# DWC_ahsata register map
Vendor: Texas Instruments
Peripheral module from a debugger description file (folder am572x).
Registers are 32-bit, read-only, reset 0x0 unless marked. A register's access mark holds for its fields unless they carry their own. Offsets are as the file gives them; lines under a group give offsets from that group; [hi:lo] are bit positions; {n}, {i} and the like mark numbered series; 'fields as' and 'values as' point back to an identical list; <NAME> marks a mode.

## DWC_ahsata
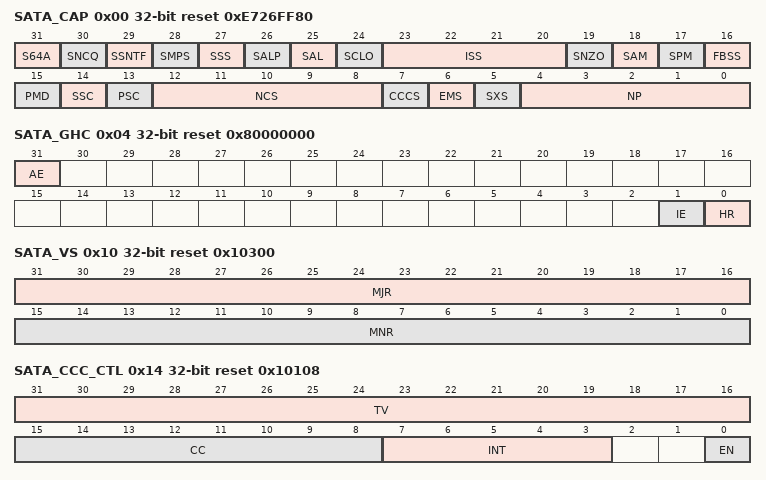
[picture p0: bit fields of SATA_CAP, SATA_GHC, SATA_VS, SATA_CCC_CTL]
0x00 SATA_CAP access not given reset 0xE726FF80 — Capabilities register: Basic capabilities of the SATA AHCI core. Some fields can be written once after reset, read-only.
  [31] S64A ro — Supports 64-bit addressing
    1=64-bit addressing supported; 0=32-bit addressing supported
  [30] SNCQ ro — Supports NCQ (Native Command Queuing) Controller supports SATA NCQ by handling DMA setup FIS natively.
    1=YES (Supported); 0=NO (Not supported)
  [29] SSNTF ro — Supports SNotification register Controller supports SATA_PxSNTF (SNotification) register and its associated functionality.
    1=YES (Supported); 0=NO (Not supported)
  [28] SMPS — Supports mechanical presence switch Support of a mechanical presence switch for hot plug operation, depending on integration Writable once after power up, read-only afterward (access RW WSpecial)
    0=NO (Not supported); 1=YES (Supported)
  [27] SSS — Supports staggered spin-up Controller can support this feature through SATA_PxCMD.SUD Writable once after power up, read-only afterward (access RW WSpecial)
    0=NO (Not supported); 1=YES (Supported)
  [26] SALP ro — Supports aggressive link power management
    1=YES (Supported); 0=NO (Not supported)
  [25] SAL ro — Supports Activity LED
    1=YES (Supported); 0=NO (Not supported)
  [24] SCLO ro — Supports command list override Supports the SATA_PxCMD.CLO bit functionality for enumeration of PM devices
    1=YES (Supported); 0=NO (Not supported)
  [23:20] ISS ro — Interface speed support Maximum speed the HBA can support
    3=ISS_3_r (Gen 3 = 6 Gbps); 2=ISS_2_r (Gen 2 = 3 Gbps); 1=1G5 (Gen 1 = 1.5 Gbps)
  [19] SNZO ro — Supports Non-zero DMA offsets
    1=YES (Supported); 0=NO (Not supported)
  [18] SAM ro — Supports AHCI mode only SATA controller supports AHCI mode only and does not support legacy, task file-based register interface.
    1=YES (Supported); 0=NO (Not supported)
  [17] SPM ro — Supports PM (Port Multiplier) SATA controller supports command-based switching PM on any port.
    1=YES (Supported); 0=NO (Not supported)
  [16] FBSS ro — FIS-based switching supported Support of PM FIS-based switching.
    1=YES (Supported); 0=NO (Not supported)
  [15] PMD ro — PIO Multiple DRQ Support of multiple DRQ block data transfers for the PIO command protocol
    1=YES (Supported); 0=NO (Not supported)
  [14] SSC ro — SLUMBER state capable Support of transitions to the interface SLUMBER power management state
    1=YES (Supported); 0=NO (Not supported)
  [13] PSC ro — PARTIAL state capable Support of transitions to the interface PARTIAL power management state
    1=YES (Supported); 0=NO (Not supported)
  [12:8] NCS ro — Number of command slots: slots supported by the SATA controller, minus 1
    31=NCS_31_r (32 command slots)
  [7] CCCS ro — Command completion coalescing supported
    1=YES (Supported); 0=NO (Not supported)
  [6] EMS ro — Enclosure management supported
    1=YES (Supported); 0=NO (Not supported)
  [5] SXS ro — Supports external SATA
    1=YES (Supported); 0=NO (Not supported)
  [4:0] NP ro — Number of ports: ports supported by the SATA controller, minus 1
    1=2p (2 ports); 0=1p (1 port)
0x04 SATA_GHC access per field reset 0x80000000 — Global HBA control
  [31] AE ro — AHCI enable Always set because SATA controller supports AHCI mode only, as indicated by the SATA_CAP.SAM = 1
  [1] IE rw — Interrupt enable Global enable of SATA controller interrupts. Reset on global reset (SATA_GHC.HR = 1).
    0=dis (All interrupt sources from all ports are disabled (masked).); 1=en (Interrupts are enabled and any SATA controller interrupt event causes interrupt output assertion.)
  [0] HR rw — HBA reset Global reset control
    0=noaction; 1=reset (Start global reset: All state machines that relate to data transfers and queuing return to an IDLE state, and all ports are reinitialized by sending COMRESET if staggered spin-up is not supported. If staggered spin-up is supported, it is the responsibility of the software to spin up each port after this reset completes.); 1=ongoing (Reset is ongoing.); 0=done (Reset is inactive (done).)
0x08 SATA_IS access not given — Interrupt status Indicates which port has a pending interrupt
  [0] IPS — Interrupt pending status. Bit-significant field. Bits are set by ports that have interrupt events pending in the SATA_PxIS bits and enabled in SATA_PxIE. Set bits are cleared by software writing 1 to them. (access RW W1toClr)
0x0C SATA_PI access not given — Ports implemented Indicates which ports are exposed by the SATA controller and available for use
  [0] PI — Ports implemented. Bit-significant field. Writable once after power up, read-only afterward. If a bit is set (1), the corresponding port is available; else (0) it is not. Only bits 0 to SATA_CAP.NP can be set to 1. At least one bit must be set to 1. (access RW WSpecial)
0x10 SATA_VS reset 0x10300 — AHCI version supported: 1.3 WARNING: Controller complies fully with AHCI version 1.10 and also complies with AHCI version 1.3 except for FIS-based switching, which is not currently supported.
  [31:16] MJR — Major Version Number: 1
  [15:0] MNR — Minor Version Number: 3.00
0x14 SATA_CCC_CTL access per field reset 0x10108 — CCC (Command Completion Coalescing) control Used to configure the CCC feature for the SATA controller Reset on global reset
  [31:16] TV rw — Time-out value. Specifies the CCC time-out value in 1-ms intervals Loaded prior to enabling CCC; becomes read-only when SATA_CCC_CTL.EN = 10x1 - 0xFFFF: timeout slectable between within the range (1 - 65535 ) ms. enum=1 .
    0=no (Reserved value; do not use.)
  [15:8] CC rw — Command completions Number of command completions necessary to cause a CCC interrupt Loaded prior to enabling CCC, becomes read-only when SATA_CCC_CTL.EN = 10x1 - 0xFF: specifies the number of commands upon which completion a CCC interrupt is generated. The number of commands to complete before interrupt is triggered are selectable within the range ( 1 - 255 ) commands. enum=count1 .
    0=nocount (CCC interrupts generated based on the timer, not on completed commands count)
  [7:3] INT ro — Interrupt Number of the interrupt used by the CCC feature, using the number of ports configured for the core When a CCC interrupt occurs, the SATA_IS.IPS[INT] bit is set to 1.
  [0] EN rw — Enable CCC enable
    0=dis (CCC feature is disabled and no CCC interrupts are generated. .TV and .CC are writable.); 1=en (CCC feature is enabled and CCC interrupts can be generated based on the time-out or command completion conditions. All other fields are read-only.)
0x18 SATA_CCC_PORTS access per field — CCC ports Specifies the ports that are coalesced as part of the CCC feature when .EN = 1 Reset on global reset
  [0] PRT rw — Ports Bit-significant field Set a bit to 1 to make the corresponding port part of the CCC feature. Bits set to 1 in this register have the same bit set to 1 in register PI.
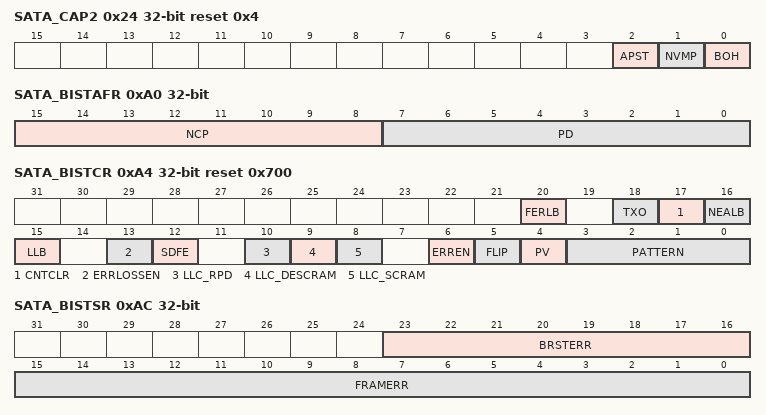
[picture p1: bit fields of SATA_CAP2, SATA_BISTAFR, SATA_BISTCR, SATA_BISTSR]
0x24 SATA_CAP2 reset 0x4 — Extended capabilities
  [all] fields
    1=YES (Supported); 0=NO (Not supported)
  [2] APST — Automatic PARTIAL to SLUMBER transitions
  [1] NVMP — NVMHCI present
  [0] BOH — BIOS/OS Handoff
0xA0 SATA_BISTAFR — Built-In, Self-Test (BIST) Activate FIS Register Reset on global reset or port reset
  [15:8] NCP — Noncompliant pattern Least significant byte of the received BIST Activate FIS second DWORD (bits [7:0]). This value defines the required pattern for far-end transmit-only mode (SATA_BISTAFR.PD =0x80 or 0xA0). If none of the listed values is decoded, the simultaneous switching pattern is transmitted by default.
    74=LFTP (High frequency test pattern (HFTP)); 127=LFTP (Simultaneous switching outputs pattern (SSOP)); 241=LFTP (Low transition density pattern (LTDP)); 139=LFTP (Lone Bit pattern (LBP)); 181=LFTP (High transition density pattern (HTDP)); 126=LFTP (Low frequency test pattern (LFTP)); 120=LFTP (Mid frequency test pattern (MFTP)); 171=LFTP (Low frequency spectral component pattern (LFSCP))
  [7:0] PD — Pattern definition Pattern definition field of the received BIST Activate FIS - bits [23:16] of the first DWORD. Puts the SATA controller in one of the listed BIST modes
    16=fer (Far-end retimed); 192=feto (Far-end transmit only); 224=fetowsb (Far-end transmit only with scrambler bypassed); 8=fea (Far-end analog (if PHY supports this mode))
0xA4 SATA_BISTCR access per field reset 0x700 — BIST control register Reset on global reset or port reset
  [20] FERLB wo — Far-end retimed loopback
    0=noaction; 1=action (Puts the DWC_ahsata link into far-end retimed mode without the BIST activate FIS, regardless of whether the device is connected or disconnected (link in NOCOMM state)); 0=rr0 (Read returns 0)
  [18] TXO wo — Transmit only
    0=noaction; 1=rr0 (Initiate transmission of one of the noncompliant patterns defined by the.PATTERN value when the device is disconnected.)
  [17] CNTCLR wo — Counter clear Clears BIST error count registers
    0=noaction; 1=action (Clear, , and registers); 0=rr0 (Read returns 0)
  [16] NEALB wo — Near-end analog loopback This mode should be initiated in the PARTIAL or SLUMBER power state or with the device disconnected from the port PHY (link NOCOMM state). BIST Activate FIS is not sent to the device in this mode.
    0=noaction; 1=PHY_1 (Places the port PHY in near-end analog loopback mode..PATTERN bit field contains the appropriate pattern.)
  [15] LLB rw — Lab Loopback Mode Masks out phy_sig_det from the OOB detector in BIST Loopback Mode. To exit BIST Loopback mode, clear the register bit then issue COMRESET / receive COMINIT.
  [13] ERRLOSSEN rw — Always keep this bit at default value.
  [12] SDFE rw — Signal detect feature enable Not affected by global reset or port reset
    0=dis (Link layer feature to handle unstable/absent phy_sig_det signal is disabled.); 1=en (Link layer feature to handle unstable/absent phy_sig_det signal is enabled.)
  [10] LLC_RPD rw — Link layer control, repeat primitive drop In normal mode, the function can be changed only during port reset (SATA_PxSCTL.DET = 0x1).
    0=Repeat primitive drop function disabled in normal mode, enabled in BIST mode; 1=Repeat primitive drop function enabled in normal mode, disabled in BIST mode
  [9] LLC_DESCRAM rw — Link layer control, descrambler In normal mode, the function can be changed only during port reset (SATA_PxSCTL.DET = 0x1).
    0=Descrambler disabled in normal mode, enabled in BIST mode; 1=Descrambler enabled in normal mode, disabled in BIST mode
  [8] LLC_SCRAM rw — Link layer control, scrambler In normal mode, the function can be changed only during port reset (SATA_PxSCTL.DET = 0x1). Hardware–cleared (enabled) when the port enters a responder far-end transmit BIST mode with scrambling enabled (SATA_BISTAFR.PD = 0x80).
    0=Scrambler disabled in normal mode, enabled in BIST mode; 1=Scrambler enabled in normal mode, disabled in BIST mode
  [6] ERREN rw — Error enable Allow or filter (disable) PHY internal errors outside the FIS boundary to set corresponding SATA_PxSERR bits
    0=Filter errors outside the FIS; allow errors inside the FIS; 1=Allow errors outside or inside the FIS
  [5] FLIP rw — Flip disparity Change disparity of the current test pattern to the opposite each time its state is changed by software.
  [4] PV rw — Pattern version Selects either short or long version of the SSOP, HTDP, LTDP, LFSCP, COMP pattern
    0=Short pattern version; 1=Long pattern version
  [3:0] PATTERN rw — Pattern Defines one of the listed SATA-compliant patterns for far-end retimed/ far-end analog/ near-end analog initiator modes, or noncompliant patterns for transmit-only responder mode when initiated by software writing to the SATA_BISTCR.TXO bit
    0=mftp (Simultaneous switching outputs pattern (SSOP)); 1=mftp (High transition density pattern (HTDP)); 2=htdp (Low transition density pattern (LTDP)); 3=hftp (Low frequency spectral component pattern (LFSCP)); 4=ssop (Composite pattern (COMP)); 5=ltdp (Lone bit pattern (LBP)); 6=lftp (Mid-frequency test pattern (MFTP)); 7=comp (High frequency test pattern (HFTP)); 8=lbp (Low frequency test pattern (LFTP))
0xA8 SATA_BISTFCTR — BIST frame-information-structure CounT register Received BIST FIS count in the loopback initiator far-end retimed, far-end analog, and near-end analog modes. Updated each time a new BIST FIS is received. Reset by global reset, port reset (COMRESET), or by writing 1 to .CNTCLR Does not roll over and freezes when the FFFF_FFFFh value is reached. It takes approximately 65 hours of continuous BIST operation to reach this value.
  [31:0] COUNT — BIST FIS Count
0xAC SATA_BISTSR — BIST status register Errors detected in the received BIST FIS in the loopback initiator far-end retimed, far-end analog, and near-end analog modes Updated each time a new BIST FIS is received Reset on global reset, port reset (COMRESET), or by writing 1 to .CNTCLR
  [23:16] BRSTERR — Burst error count. Accumulated each time a burst error condition is detected: DWORD error is detected in the received frame and 1.5 seconds (27,000 frames) passed since the previous burst error was detected. Value does not roll over and freezes at FFh.
    255=max (Max error count reached or exceeded); 0=zero (No error detected)
  [15:0] FRAMERR — Frame error count. New value is added to the old value each time a new BIST frame with a CRC error is received. Does not roll over and freezes at FFFFh
    0xFFFF=max (Maximum error count reached or exceeded.); 0=zero (No error detected)
0xB0 SATA_BISTDECR — BIST double-word error count register Number of DWORD errors detected in the received BIST frame in the loopback initiator far-end retimed, far-end analog, and near-end analog modes Updated each time a new BIST frame is received, when the parameter BIST_MODE = DWORD. Reset on global reset, port reset (COMRESET), or by writing 1 to .CNTCLR.
  [31:0] DWERR — DWORD error count. New value is added to the old value each time a new BIST frame is received. The DWERR value does not roll over, and freezes when it exceeds 0xFFFF_F000.
    0=zero (No error detected); 0xFFFFF000=max (Max error count reached or exceeded)
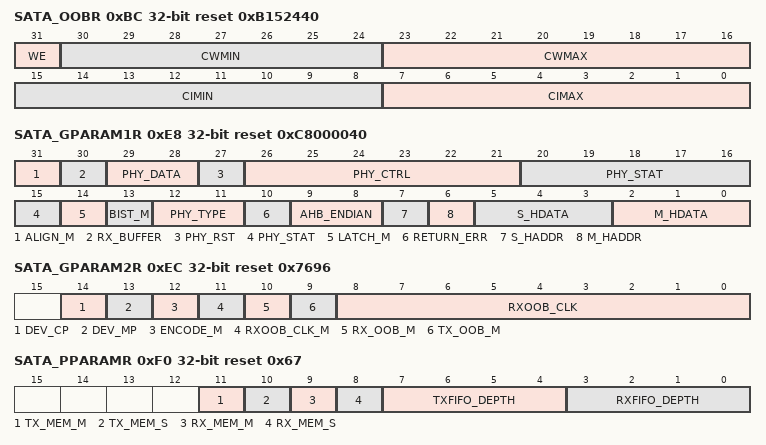
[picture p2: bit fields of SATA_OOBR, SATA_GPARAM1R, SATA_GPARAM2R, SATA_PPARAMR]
0xBC SATA_OOBR access not given reset 0xB152440 — OOB (Out Of Band Register) register Controls the link layer OOB detection counters
  [31] WE rw — WRITE_ENABLE
    0=no (bits [30:0] are read-only.); 1=yes (bits [30:0] can be written.)
  [30:24] CWMIN — COMWAKE_MIN, in OOB rx clock cycles Read-only when SATA_OOBR.WE = 0 (access RW WSpecial)
  [23:16] CWMAX — COMWAKE_MAX, in OOB rx clock cycles Read-only when SATA_OOBR.WE = 0 (access RW WSpecial)
  [15:8] CIMIN — COMINIT_MIN, in OOB rx clock cycles Read-only when SATA_OOBR.WE = 0 (access RW WSpecial)
  [7:0] CIMAX — COMINIT_MAX, in OOB rx clock cycles Read-only when SATA_OOBR.WE=0 (access RW WSpecial)
0xE0 SATA_TIMER1MS access per field reset 0x186A0 — Timer 1 ms Configuration to generate the 1-ms tick for the CCC logic Must be initialized before using the CCC feature Reset on power up, not affected by global reset
  [19:0] TIMV rw — OCP bus clock frequency in kHz (for example, reset value is 100,000 = 100 MHz)
0xE8 SATA_GPARAM1R reset 0xC8000040 — Global parameters register 1 Hardware configuration of the DWC AHCI SATA core
  [31] ALIGN_M — RX data alignment
    1=yes; 0=no
  [30] RX_BUFFER — RX data buffer implemented
    1=yes; 0=no
  [29:28] PHY_DATA — PHY data width (in 8- or 10-bit characters)
    2=PHY_DATA_2_r (4 characters); 1=PHY_DATA_1_r (2 characters); 0=PHY_DATA_0_r (1 character)
  [27] PHY_RST — PHY reset mode
    1=hi (High); 0=lo (Low)
  [26:21] PHY_CTRL — PHY control width (in bits)
  [20:15] PHY_STAT — PHY status width (in bits)
  [14] LATCH_M — Test mode lock-up latches
    1=yes; 0=no
  [13] BIST_M — BIST loopback checking depth
    1=DWORD; 0=FIS
  [12:11] PHY_TYPE — PHY interface type0x2, 0x3: Reserved enum=config .
    1=snps (Preset); 0=Configurable
  [10] RETURN_ERR — Error response on illegal access
    1=yes; 0=no
  [9:8] AHB_ENDIAN — Endianness of master and slave
    2=conf (Pin-configurable dynamic endianness); 1=big (Big-endian); 0=Little-endian
  [7] S_HADDR — Slave address bus width
    1=64-bit address; 0=32-bit address
  [6] M_HADDR — Master address bus width
    1=64-bit address; 0=32-bit address
  [5:3] S_HDATA — Slave Data Bus Width
    3=256-bit; 2=128-bit; 1=64-bit; 0=32-bit
  [2:0] M_HDATA — Master Data Bus Width
    3=256-bit; 2=128-bit; 1=64-bit; 0=32-bit
0xEC SATA_GPARAM2R reset 0x7696 — Global parameters register 2 Hardware configuration of the DWC AHCI SATA core, continued
  [14] DEV_CP — Cold presence detection implemented in core
    1=yes; 0=no
  [13] DEV_MP — Mechanical presence switch implemented in core
    1=yes; 0=no
  [12] ENCODE_M — 8b/10b Encoding/decoding implemented in core
    1=yes; 0=no
  [11] RXOOB_CLK_M — RX OOB clocking mode:
    1=sep (RX OOB detection uses separate clock); 0=rx (Rx OOB detection uses RX clock)
  [10] RX_OOB_M — RX OOB mode: sequence generation implemented
    1=yes; 0=no
  [9] TX_OOB_M — TX OOB mode: sequence generation implemented
    1=yes; 0=no
  [8:0] RXOOB_CLK — RX OOB clock frequency, in MHz
0xF0 SATA_PPARAMR reset 0x67 — Port parameter register Hardware configuration of the DWC AHCI SATA core port selected by .PSEL
  [11] TX_MEM_M — TX FIFO memory mode:
    1=Synchronous; 0=Asynchronous
  [10] TX_MEM_S — TX FIFO memory selection:
    1=int (Internal memory); 0=ext (External memory)
  [9] RX_MEM_M — RX FIFO memory mode:
    1=Synchronous; 0=Asynchronous
  [8] RX_MEM_S — RX FIFO memory selection:
    1=int (Internal memory); 0=ext (External memory)
  [7:4] TXFIFO_DEPTH — Tx FIFO Depth, in dwords (log2)
    3=TXFIFO_DEPTH_3_r (8 dwords); 4=TXFIFO_DEPTH_4_r (16 dwords); 5=TXFIFO_DEPTH_5_r (32 dwords); 6=TXFIFO_DEPTH_6_r (64 dwords)
  [3:0] RXFIFO_DEPTH — Rx FIFO Depth, in dwords (log2)
    4=RXFIFO_DEPTH_4_r (16 dwords); 5=RXFIFO_DEPTH_5_r (32 dwords); 6=RXFIFO_DEPTH_6_r (64 dwords); 7=RXFIFO_DEPTH_7_r (128 dwords)
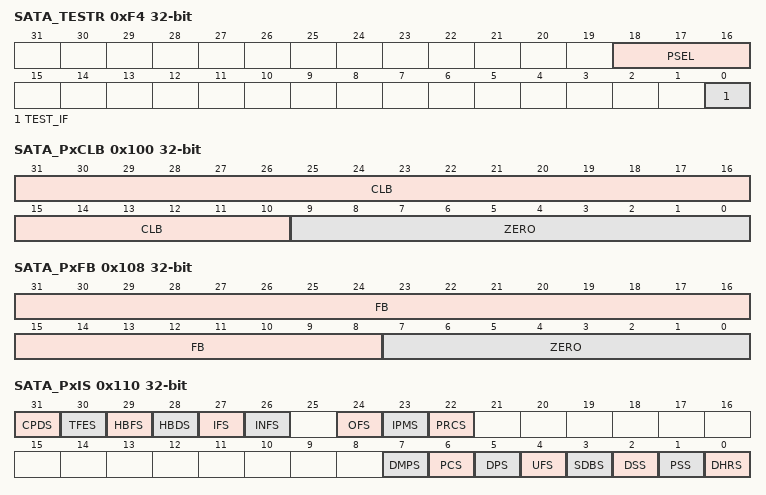
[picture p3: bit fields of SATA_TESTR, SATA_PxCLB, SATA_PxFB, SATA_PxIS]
0xF4 SATA_TESTR access per field — Test register Puts the SATA controller slave interface in a test mode and selects a port for BIST operation
  [18:16] PSEL rw — Port select: Selects the port for BIST operation
    0=Port 0 is selected
  [0] TEST_IF rw — Test interface
    0=default (Normal mode: read-back value of some registers might not match the value written, depending on ongoing operations.); 1=Test mode: Normal operation is disabled; read-back value of the registers match the value written. The following registers/fields can be accessed in this mode: - .IE - .NCP and .PD bits become writable. - .LLC .ERREN .FLIP .PV, and .PATTERN - , , become writeable. - / , / - .UFS and write-1-to-clear bits become writeable. - - .ASP .ALPE .DLAE .ATAPI and .PMA - , become writeable. - - (write-1-to-clear) bits become writeable. Notes: 1) Interrupt is asserted if any IS register bit is set after setting the corresponding and bits, and .IE = 1. 2) .SMPS/SSS, , .ESP/CPD/MPSP/HPCP cannot be used in test mode. They are written once after POR and become read-only. 3) Global reset must be issued (.HR=1) after the TEST_IF bit is cleared following the test mode operation.
0xF8 SATA_VERSIONR reset not defined — Version register
  [31:0] VERSION — Version of DWC SATA controller, ASCII. See.
0xFC SATA_IDR reset not defined — ID register, containing the 32-bit Highlander (HL) revision.
  [31:0] REVISION — See.
0x100 SATA_PxCLB access per field — Port command List base address 32-bit base physical address for the command list for this port. Used when fetching commands to execute. The structure pointed to by this address range is 1 KiB in length.
  [31:10] CLB rw — Command list base address (bits 31:10)
  [9:0] ZERO ro — Always 0 as address is 1 KiB-aligned
0x104 SATA_PxCLBU rw — Port Command List Base Upper address Upper half of the 64-bit base physical address for the command list for this Port. Used when fetching commands to execute. Remains all 0 when in 32-bit mode. Reserved & read-only when CAP.S64A=0
  [31:0] CLBU — Command List Base Upper Address (bits 63:32)
0x108 SATA_PxFB access per field — Port Frame-information-structure Base address 32-bit base physical address for received FISes for this port. The structure pointed to by this address range is 256 bytes in length.
  [31:8] FB rw — FIS base address (bits 31:8)
  [7:0] ZERO ro — Always 0 as address is 256-bytes aligned
0x10C SATA_PxFBU rw — FIS Base Upper Address Upper half of the 64-bit base physical address for received FISes for this port. Remains all 0 with a 32-bit SW driver. Reserved & read-only when CAP.S64A=0
  [31:0] FBU — FIS Base Upper Address (bits 63:32)
0x110 SATA_PxIS access not given — Port interrupt status Bits are set by internal conditions and cleared (when possible) by writing 1 to them. Reset on global reset.
  [31] CPDS — Cold port detect status Set when the pX_cp_det input changes its state due to the insertion or removal of a device Valid only if the port supports cold presence detection as indicated by the SATA_PxCMD.CPD bit set to 1. (access RW W1toClr)
    0=noaction; 1=Clear event; 1=event (IRQ event active); 0=noevent (Event inactive)
  [30] TFES — Task file error status Set whenever the SATA_PxTFD.STS register is updated by the device and the error bit (bit 0) is set. (access RW W1toClr)
    values as CPDS
  [29] HBFS — Host bus fatal error status Set when master (DMA) detects an ERROR response from the slave (access RW W1toClr)
    values as CPDS
  [28] HBDS — Host bus data error status This bit is always cleared to 0. (access RW W1toClr)
    values as CPDS
  [27] IFS — Interface fatal error status This bit is set when any of the following conditions is detected: 1) SYNC escape is received from the device during H2D register or data FIS transmission. 2) One or more of the following errors are detected during data FIS transfer: - 10B to 8B Decode Error (SATA_PxSERR.DIAG_B) - Protocol (SATA_PxSERR.ERR_P) - CRC (SATA_PxSERR.DIAG_C) - Handshake (SATA_PxSERR.DIAG_H) - PHY not ready (SATA_PxSERR.ERR_C) 3) Unknown FIS is received with good CRC, but the length exceeds 64 bytes. 4) PRD table byte count is 0. 5) DMA setup FIS is received with a TAG corresponding to inactive (SATA_PxSACT bit is cleared) command slot. Port DMA transitions to a fatal state until the software clears SATA_PxCMD.ST bit or resets the interface by way of port reset or global reset. (access RW W1toClr)
    values as CPDS
  [26] INFS — Interface nonfatal error status Set when any of the following conditions is detected: 1) One or more of the following errors are detected during nondata FIS transfer: - 10b to 8b decode error (SATA_PxSERR.DIAG_B) - Protocol (SATA_PxSERR.ERR_P) - CRC (SATA_PxSERR.DIAG_C) - Handshake (SATA_PxSERR.DIAG_H) - PHY not ready (SATA_PxSERR.ERR_C) 2) Command list underflow during read operation (that is, DMA read) when the software builds a command table that has more total bytes than the transaction given to the device. In both cases port operation continues normally. When an error is detected during nondata FIS transmission, this FIS is retransmitted continuously until it succeeds, or until the software times out and resets the interface. (access RW W1toClr)
    values as CPDS
  [24] OFS — Overflow status Set when command list overflow is detected during read or write operation when the software builds command table that has fever total bytes than the transaction given to the device. Port DMA transitions to a fatal state until the software clears SATA_PxCMD.ST bit or resets the interface by way of port reset or global reset. (access RW W1toClr)
    values as CPDS
  [23] IPMS — Incorrect PM status FIS received from a device in which the PM field did not match what was expected May be set during enumeration of devices on a PM due to the normal PM enumeration process Must be used only after enumeration is complete on the PM (access RW W1toClr)
    values as CPDS
  [22] PRCS ro — PhyRdy change status Reflects the state of SATA_PxSERR.DIAG_N To clear this bit, clear the SATA_PxSERR.DIAG_N bit to 0.
    1=change (Internal pX_phy_ready signal changed state); 0=nochange (Internal pX_phy_ready signal has not changed state since its last reset.)
  [7] DMPS — Device mechanical presence status Set when the pX_mp_switch input changes its state as a result of a mechanical switch attached to this port opening or closing Valid only when SATA_CAP.SMPS and SATA_PxCMD.MPSP are set (access RW W1toClr)
    values as CPDS
  [6] PCS ro — Port connect change status This bit reflects the state of the SATA_PxSERR.DIAG_X bit. Cleared only when SATA_PxSERR.DIAG_X is cleared
    1=Change in current connect status; 0=No change in current connect status
  [5] DPS — Descriptor processed A PRD with the I bit set has transferred all of its data. Note. This is an opportunistic interrupt and must not be used to definitively indicate the end of a transfer. Two PRD interrupts could occur close enough together that the second interrupt is missed when the first PRD interrupt is cleared. (access RW W1toClr)
    values as CPDS
  [4] UFS ro — Unknown FIS interrupt An unknown FIS was received and has been copied into system memory. Cleared to 0 by the software clearing the SATA_PxSERR.DIAG_F bit to 0. Note: The UFS bit does not directly reflect the SATA_PxSERR.DIAG_F bit. SATA_PxSERR.DIAG_F bit is set immediately when an unknown FIS is detected, whereas the UFS bit is set when that FIS is posted to memory. The software should wait to act on an unknown FIS until the UFS bit is set to 1 or the two bits may become out of sync.
    1=event (IRQ event active); 0=noevent (Event inactive)
  [3] SDBS — Set device bits interrupt A Set Device Bits FIS is received with the I bit set and copied into system memory. (access RW W1toClr)
    values as CPDS
  [2] DSS — DMA setup FIS interrupt A DMA Setup FIS is received with the I bit set and copied into system memory. (access RW W1toClr)
    values as CPDS
  [1] PSS — PIO setup FIS interrupt A PIO Setup FIS is received with the I bit set, copied into system memory, and the data related to the FIS is transferred. Note: This bit is set even when the data transfer resulted in an error. (access RW W1toClr)
    values as CPDS
  [0] DHRS — Device to host register FIS interrupt A D2H register FIS is received with the I bit set and copied into system memory. (access RW W1toClr)
    values as CPDS
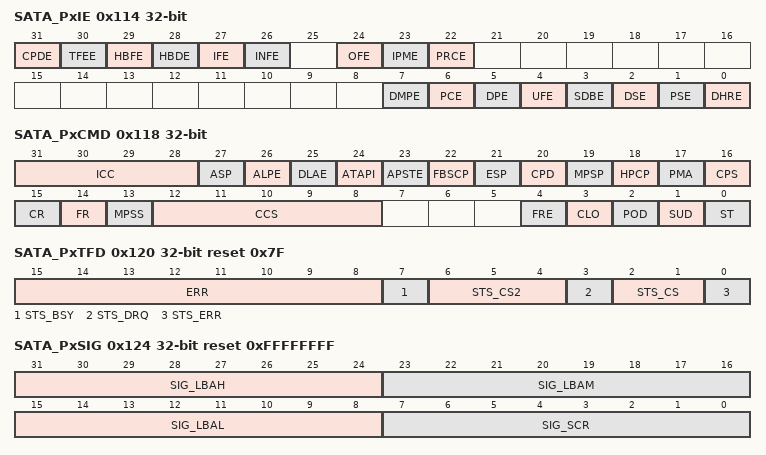
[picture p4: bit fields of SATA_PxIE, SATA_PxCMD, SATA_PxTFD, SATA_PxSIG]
0x114 SATA_PxIE access per field — Port interrupt enable Enables and disables the reporting of the corresponding interrupt to system software When a bit is set (1), .IE = 1, and the corresponding interrupt condition in is active, then the SATA controller interrupt output is asserted. When a bit is cleared (0), interrupt sources are still reflected in the status registers. Reset on global reset
  [all] fields
    0=dis (Interrupt disabled); 1=en (Interrupt enabled)
  [31] CPDE rw — Cold port detect enable
  [30] TFEE rw — Task file error enable
  [29] HBFE rw — Host bus fatal error enable
  [28] HBDE rw — Host bus data error enable
  [27] IFE rw — Interface fatal error enable
  [26] INFE rw — Interface non fatal error enable
  [24] OFE rw — Overflow enable
  [23] IPME rw — Incorrect PM enable
  [22] PRCE rw — PhyRdy change enable
  [7] DMPE rw — Device mechanical presence enable
  [6] PCE rw — Port connect change enable
  [5] DPE rw — Descriptor processed interrupt enable
  [4] UFE rw — Unknown FIS interrupt enable
  [3] SDBE rw — Set device bits interrupt enable
  [2] DSE rw — DMA setup FIS interrupt enable
  [1] PSE rw — PIO setup FIS interrupt enable
  [0] DHRE rw — Device to host register FIS interrupt enable
0x118 SATA_PxCMD access per field — Port command
  [31:28] ICC rw — Interface communication control Control of power management states of the interface If the link layer is in the L_IDLE state, writes cause the port to request a transition to a given interface state. If the link layer is not in the L_IDLE state, writes have no effect. When a nonreserved, non-0 (No-Op) value is written, the core performs the action and clears the field back to 0 (Idle)
    0=noop; 0=SLUMBER (Port is ready to accept a new interface control command, although the transition to the previously selected state might not have occurred yet.); 1=active; 2=idle (PARTIAL. SATA device can reject the request and the interface then remains in its current state.); 6=PARTIAL (SLUMBER. SATA device can reject the request and the interface then remains in its current state.)
  [27] ASP rw — Aggressive SLUMBER/PARTIAL
    0=PARTIAL (If.ALPE = 1, the port aggressively enters the PARTIAL state when it clears the register and the register is cleared when it clears the register and is cleared.); 1=SLUMBER (If.ALPE = 1, the port aggressively enters the SLUMBER state when it clears the and the register is cleared or when it clears the register and is cleared.)
  [26] ALPE rw — Aggressive link power management enable
    0=dis (Aggressive power management state transition is disabled.); 1=en (Port aggressively enters a lower link power state (PARTIAL or SLUMBER) based on the setting of.ASP.)
  [25] DLAE rw — Drive LED on ATAPI enable
    0=dis (LED is never enabled.); 1=en (Port asserts the pX_act_led output when commands are active and.ATAPI = 1.)
  [24] ATAPI rw — Device is ATAPI Used by the port to determine whether or not to assert pX_act_led output when commands are active.
    0=no (Connected device is not an ATAPI.); 1=yes (Connected device is an ATAPI.)
  [23] APSTE rw — Auto PARTIAL to SLUMBER transition enable
    0=dis (No automatic transition from PARTIAL to SLUMBER); 1=en (Link layer transitions from its PARTIAL power management state to SLUMBER state automatically, whether host software-, port (aggressive)-, or device-initiated.)
  [22] FBSCP rw — FIS-based Switching Capable Port May only be set to ?1? if CAP.SPM = CAP.FBSS = 1 (not the case). Writable once after power up, read-only afterwards.
    0=en (port does not support FIS-based switching.); 1=en (Port supports Port Multiplier FIS-based switching.)
  [21] ESP rw — External SATA port Writable once after power up, read-only afterward
    0=int (Port signal-only connector is not externally accessible.); 1=ext (Port signal-only connector is externally accessible..SXS is also set to 1. Mutually exclusive with .HPCP)
  [20] CPD rw — Cold presence detect Writable once after power up, read-only afterward
    0=no (Platform does not support cold presence detection on this port.); 1=yes (Platform supports cold presence detection on this port. .HPCP should be set to 1.)
  [19] MPSP rw — Mechanical presence switch attached to port Writable once after power up, read-only afterward
    0=no (Platform does not support a mechanical presence switch on this port.); 1=yes (Platform supports a mechanical presence switch attached to this port. .HPCP should be set to 1.)
  [18] HPCP rw — Hot plug capable port Writable once after power up, read-only afterward
    0=no (Port signal and power connectors are not externally accessible.); 1=yes (Port signal and power connectors are externally accessible through a joint signal-power connector for blindmate device hot plug.)
  [17] PMA rw — PM attached Software is responsible for detecting the presence of a PM. There is no autodetection.
    0=no (No port Multiplier is attached to this Port); 1=yes (Port Multiplier is attached to this Port)
  [16] CPS ro — Cold presence state Reports whether a device is currently detected on this port as indicated by the pX_cp_det input state (assuming SATA_PxCMD.CPD = 1).
    1=yes (Device detected); 0=no (No device detected)
  [15] CR ro — Command list running For details, see the AHCI state-machine in Section 5.3.2 of the AHCI specification.
    1=running (Command list DMA engine for this port is running.); 0=stopped (Command list is stopped for this port.)
  [14] FR ro — FIS receive running For details, see Section 10.3.2 of the AHCI specification.
    1=running (FIS receive DMA engine for the port is running.); 0=stopped (FIS receive DMA engine for the port is stopped.)
  [13] MPSS ro — Mechanical presence switch state Reports the state of a mechanical presence switch attached to this port as indicated by the pX_mp_switch input state (assuming SATA_CAP.SMPS = 1 and SATA_PxCMD.MPSP = 1) Cleared to 0 when SATA_CAP.SMPS = 0
    1=open (Switch is open.); 0=closed (Switch is closed.)
  [12:8] CCS ro — Current command slot This field is valid when SATA_PxCMD.ST is set to 1 and is set to the command slot value of the command currently issued by the port. When SATA_PxCMD.ST transitions from 1 to 0, this field is reset to 0x00. After SATA_PxCMD.ST transitions from 0 to 1, the highest priority slot to issue from next is command slot 0. After the first command is issued, the highest priority slot to issue from next is SATA_PxCMD.CCS + 1. For example, after the port issues its first command, if CCS = 0x00 and SATA_PxCI is set to 0x3, the next command issued is from command slot 1.
  [4] FRE rw — FIS receive enable Must not be set until SATA_PxFB / SATA_PxFBU is programmed with a valid pointer to the FIS receive area Base can be moved after clearing FRE and waiting for FR to clear to 0.
    0=dis (Received FISes are not accepted by the port, except for the first D2H register FIS after the initialization sequence, and no FISes are posted to the FIS receive area.); 1=en (Port can post received FISes into the FIS receive area pointed to by and .)
  [3] CLO rw — Command list override
    0=noaction (No effect); 1=override (Request to clear.STS_BSY and .STS_DRQ to 0. Use only immediately prior to setting .ST bit to 1 from a previous value of 0. Any other case results in indeterminate behavior.); 1=active (Override is active,.STS_BSY and .STS_DRQ are being cleared.); 0=idle (Override is inactive.)
  [2] POD rw — Power-on device Writable if SATA_PxCMD.CPD = 1 (cold presence detection enabled), otherwise read-only -1.
    0=no (Disabled); 1=yes (Port asserts the pX_cp_pod output pin so that it can be used to provide power to a cold-presence detectable port.)
  [1] SUD rw — Spin-up device Writable if SATA_CAP.SSS = 1 (staggered spin-up supported), else read-only 1. Read-only-0 on power-up until SATA_CAP.SSS bit is written with the required value.
    0=noaction (Clearing the bit from 1 to 0 causes no action on the interface.); 1=newEnum2 (On edge-detect from 0 to 1, the port starts a COMRESET initialization sequence to the device.)
  [0] ST rw — Start
    0=newEnum1 (Port does not process the command list. On transition from 1 to 0, the register is cleared by the port on transition to an IDLE state.); 1=start (Port processes the command list. On transition from 0 to 1, the port starts processing the command list at entry 0. must be cleared prior to setting ST to 1. For important restrictions on when ST can be set to 1, See Section 10.3.1 of the AHCI specification.)
0x120 SATA_PxTFD reset 0x7F — Port Task File Data: copies specific fields of the task file when FISes are received
  [15:8] ERR — Err: Latest copy of the task file error register
  [7] STS_BSY — Status, busy Latest copy of the 8-bit task file status register, bit 7 STS_BSY = Interface is busy
  [6:4] STS_CS2 — Status, command-specific Latest copy of the 8-bit task file status register, bits 6:4
  [3] STS_DRQ — Status, data request Latest copy of the 8-bit task file status register, bit 3 STS_DRQ = Data transfer is requested
  [2:1] STS_CS — Status, command-specific Latest copy of the 8-bit task file status register, bits 2:1
  [0] STS_ERR — Status, error Latest copy of the 8-bit task file status register, bit 0 STS_ERR = Error during the transfer
0x124 SATA_PxSIG reset 0xFFFFFFFF — Port signature: Signature received from a device on the first D2H register FIS. Updated once after a reset sequence.
  [31:24] SIG_LBAH — Signature, LBA high (cylinder high) register
  [23:16] SIG_LBAM — Signature, LBA mid (cylinder low) register
  [15:8] SIG_LBAL — Signature, LBA low (sector number) register
  [7:0] SIG_SCR — Signature, sector count register
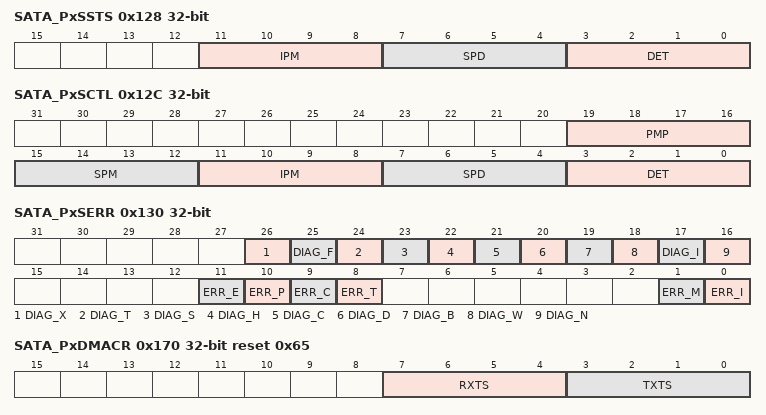
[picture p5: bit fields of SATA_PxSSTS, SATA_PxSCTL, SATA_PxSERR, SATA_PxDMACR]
0x128 SATA_PxSSTS — Port SATA status Current state of the interface and host, updated continuously and asynchronously. When the port transmits a COMRESET to the device, this register is updated to its reset values (that is, global reset, port reset, or COMINIT from the device).
  [11:8] IPM — Interface power management: Current interface state
    0=IPM_0_r (Device not present or communication not established); 1=IPM_1_r (Interface in ACTIVE state); 2=IPM_2_r (Interface in PARTIAL power management state); 6=IPM_6_r (Interface in SLUMBER power management state)
  [7:4] SPD — Current interface speed: Negotiated interface communication speed
    3=SPD_3_r (Generation 3 communication rate negotiated (6 Gbps)); 2=SPD_2_r (Generation 2 communication rate negotiated (3 Gbps)); 1=SPD_1_r (Generation 1 communication rate negotiated (1.5 Gbps)); 0=SPD_0_r (Device not present or communication not established)
  [3:0] DET — Device detection: Interface device detection and PHY state
    0=DET_0_r (No device detected and PHY communication not established); 1=DET_1_r (Device presence detected but PHY communication not established); 3=DET_3_r (Device presence detected and PHY communication established); 4=DET_4_r (PHY in offline mode as a result of the interface being disabled or running in a BIST loopback mode)
0x12C SATA_PxSCTL access per field — Port SATA control Control of SATA interface capabilities. Writes to this register result in action taken by the port PHY interface. Reads from the register return the last value written to it. Reset on global reset. Wait for at least seven periods of the slower clock (OCP or parallel serdes clock) between writes, due to the internal clock domain crossing between the transport (OCP) and link (serdes I/F) layers.
  [19:16] PMP ro — PM port: This field is not used by the AHCI.
  [15:12] SPM ro — Select power management: This field is not used by the AHCI.
  [11:8] IPM rw — Interface power management transitions allowed: Indicates which power states the HBA is allowed to transition to. If an interface power management state is disabled, the HBA is not allowed to initiate that state and the HBA must PMNAK_P any request from the device to enter that state. The two MSBs are always 2'b00 (not writable), as for all unreserved field values.
    0=No interface power management state restrictions; 1=Transitions to the PARTIAL state disabled; 2=Transitions to the SLUMBER state disabled; 3=Transitions to both PARTIAL and SLUMBER states disabled
  [7:4] SPD rw — Speed allowed: Highest allowable speed of the interface The two MSBs are always 2'b00 (not writable), as for all unreserved field values.
    0=No speed negotiation restrictions; 1=Limit speed negotiation to generation 1 communication rate; 2=Limit speed negotiation to a rate not greater than generation 2 communication rate
  [3:0] DET rw — Device detection initialization: Controls the HBA device detection and interface initialization. Can be modified only when SATA_PxCMD.ST = 0. Must have a value of 0x0 when SATA_PxCMD.ST = 1. MSB is always 1'b0 (not writable), as for all unreserved field values.
    0=No device detection or initialization action requested; 1=Perform interface communication initialization sequence to establish communication. This is functionally equivalent to a hard reset and results in the interface being reset and communications reinitialized. While this field is 1h, COMRESET is transmitted on the interface. Software must leave the DET field set to 1h for a minimum of 1 ms to ensure that a COMRESET is sent on the interface.; 4=Disable the serial ATA interface and put PHY in offline mode
0x130 SATA_PxSERR access not given — Port SATA error Detected interface errors accumulated since the last time it cleared. When set, indicates that the corresponding error condition became true one or more times since the last time cleared. Write 1 to a bit to clear it. Cleared by global reset or port reset (COMRESET).
  [26] DIAG_X — Exchanged: PHY COMINIT signal detected. Reflected inSATA_PxIS.PCS. (access RW W1toClr)
  [25] DIAG_F — Unknown FIS type: One or more FISes were received by the transport layer with good CRC, but had a type field that was not recognized/known and the length was = 64 bytes. Note: If the unknown FIS length exceeds 64 bytes, DIAG_F is not set and DIAG_T is set instead. (access RW W1toClr)
  [24] DIAG_T — Transport state transition error: Transport Layer protocol violation detected. (access RW W1toClr)
  [23] DIAG_S — Link sequence error: One or more Link state machine error conditions encountered, including device doing SYNC escape during FIS transmission. (access RW W1toClr)
  [22] DIAG_H — Handshake error: One or more R-ERRp received in response to frame transmission. May be the result of a CRC error detected by the device, a disparity or 8b/10b decoding error, or other error condition leading to a negative handshake on a transmitted frame. (access RW W1toClr)
  [21] DIAG_C — CRC error: One ore more CRC errors detected by the link layer during FIS reception. (access RW W1toClr)
  [20] DIAG_D ro — Disparity error: Not used by AHCI, always 0.
  [19] DIAG_B — 10bit-to-8bit decode error: Errors detected by the 10b8b decoder. Note: Set only when an error is detected on the received FIS data word. Not set when an error is detected on the primitive, regardless of whether it is inside or outside the FIS. (access RW W1toClr)
  [18] DIAG_W — Comm wake: Comm wake signal detected by the PHY. (access RW W1toClr)
  [17] DIAG_I — PHY internal error: Internal error detected by the PHY. Note: If the PHY does not support any errors, this bit is never set. (access RW W1toClr)
  [16] DIAG_N — PhyRdy change: Indicates that the PHY Ready signal changed state. Reflected inSATA_PxIS.PRCS. (access RW W1toClr)
  [11] ERR_E — Internal error: One or more errors detected on the master (DMA) or the slave (MMR access) interfaces. (access RW W1toClr)
  [10] ERR_P — Protocol error: Any of the following conditions: - Transport state transition error (DIAG_T) - Link sequence error (DIAG_S) - RxFIFO overflow - Link bad end error (WTRM instead of EOF received) (access RW W1toClr)
  [9] ERR_C — Nonrecovered persistent communication error: PHY Ready signal is negated due to loss of communication with the device or problems with the interface, but not after transition from ACTIVE to PARTIAL or SLUMBER power management state. (access RW W1toClr)
  [8] ERR_T — Nonrecovered transient data integrity error: Any of the following conditions are set during data FIS transfer: - ERR_P (Protocol) - DIAG_C (CRC) - DIAG_H (Handshake) - ERR_C (PHY Ready negation) (access RW W1toClr)
  [1] ERR_M — Recovered communication error: PHY Ready condition is detected after interface initialization, but not after transition from PARTIAL or SLUMBER power management state to ACTIVE state. (access RW W1toClr)
  [0] ERR_I — Recovered data integrity error: Any of the following conditions are set during non-data FIS transfer: - ERR_P (Protocol) - DIAG_C (CRC) - DIAG_H (Handshake) - ERR_C (PHY Ready negation) (access RW W1toClr)
0x134 SATA_PxSACT rw — Port SATA active (SActive): Indicates which command slots contain commands.
  [31:0] DS — Device status: Field is bit-significant. Each bit corresponds to the TAG and command slot of a native queued command, where bit 0 corresponds to TAG 0 and command slot 0. Set by Software prior to issuing a native queued command for a particular command slot. Prior to writingSATA_PxCI[TAG] to 1, software sets DS[TAG] to 1 to indicate that a command with that TAG is outstanding. The device clears bits by sending a set device bits FIS to the port. The port clears bits in this field that are set to 1 in the SActive field of the set device bits FIS. The port only clears bits that correspond to native queued commands completed successfully. Write only when SATA_PxCMD.ST bit is set to 1. Cleared when SATA_PxCMD.ST is written from 1 to 0. Not cleared by a port reset (COMRESET) or a software reset.
0x138 SATA_PxCI rw — Port command issue: Indicates that a command is constructed and may be carried out.
  [31:0] CI — Commands issue: Field is bit-significant. Each bit corresponds to a command slot, where bit 0 corresponds to command slot 0. This field is set by software to indicate to the port that a command is built in system memory for a command slot and may be sent to the device. When the port receives a FIS that clears the BSY, DRQ, and ERR bits for the command, it clears the corresponding bit in this register for that command slot. Bits in this field can only be set to 1 by software whenSATA_PxCMD.ST is set to 1. Also cleared when SATA_PxCMD.ST is written from 1 to 0 by software.
0x13C SATA_PxSNTF access not given — Port SATA notification: Used to determine if asynchronous notification events have occurred for directly connected devices and devices connected to a PM.
  [15:0] PMN — PM notify: Indicates whether a particular device with the corresponding PM port number issued a set device bits FIS to the SATA controller Port with the notification bit set: - PM Port 0h sets bit 0. - PM Port 0h sets bit 1. - etc. Write 1 to a bit to clear it. Reset on global reset but not on port reset (COMRESET) or software reset. (access RW W1toClr)
0x170 SATA_PxDMACR access per field reset 0x65 — Port DMA control register. Not AHCI-standard. Writable only when.ST = 0. Attempts to write a field value less than the minimum or more than the maximum cause the field to be set to the minimum or the maximum. Reset on global reset and port reset (COMRESET)
  [7:4] RXTS rw — Receive transaction size: DMA transaction size for receive operations (system bus write, device read).
    0=1 dword; 1=2 dwords; 2=4 dwords; 3=8 dwords; 4=16 dwords; 5=32 dwords; 6=64 dwords; maximum value for the 128-dword RX FIFO of this implementation
  [3:0] TXTS rw — Transmit transaction size: DMA transaction size for transmit operations (system bus read, device write).
    0=1 dword; 1=2 dwords; 2=4 dwords; 3=8 dwords; 4=16 dwords; 5=32 dwords; maximum value for this implementation
